# ATSAM4LC8C register map
Vendor: Atmel Corporation; Series: SAM4L; File version: A
CPU: CM4 r0p1, little endian, MPU, no FPU, 4 interrupt priority bits
Registers are 32-bit, write-only, reset 0x0 unless marked. A register's access mark holds for its fields unless they carry their own. Offsets are from the block's base; [hi:lo] are bit positions; {n}, {i} and the like mark numbered series.

## PM — Power Manager
Base 0x400E0000; register names take the prefix PM_
0x00 MCCTRL rw — Main Clock Control
  [2:0] MCSEL — Main Clock Select
    0=RCSYS (System RC oscillator); 1=OSC0 (Oscillator0); 2=PLL; 3=DFLL; 4=RC80M (80 MHz RC oscillator); 5=RCFAST (4/8/12 MHz RC oscillator); 6=RC1M (1 MHz RC oscillator)
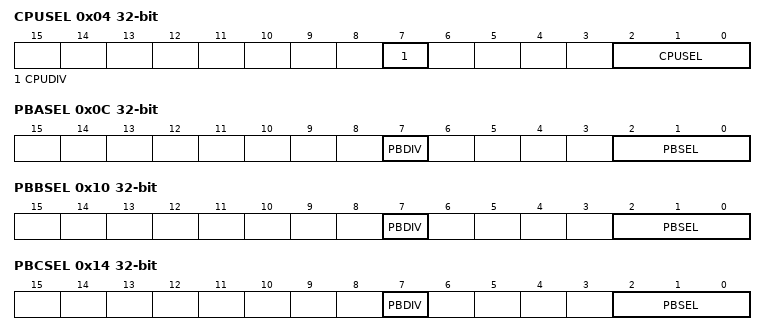
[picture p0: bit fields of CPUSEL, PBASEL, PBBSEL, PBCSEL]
0x04 CPUSEL rw — CPU Clock Select
  [7] CPUDIV — CPU Division
  [2:0] CPUSEL — CPU Clock Select
    0=fCPU:fmain. CPUDIV:; 1=fCPU:fmain / 2^(CPUSEL+1)
0x0C PBASEL rw — PBA Clock Select
  [7] PBDIV — PBA Division Select
  [2:0] PBSEL — PBA Clock Select
0x10 PBBSEL rw — PBB Clock Select
  [7] PBDIV — PBB Division Select
  [2:0] PBSEL — PBB Clock Select
0x14 PBCSEL rw — PBC Clock Select
  [7] PBDIV — PBC Division Select
  [2:0] PBSEL — PBC Clock Select
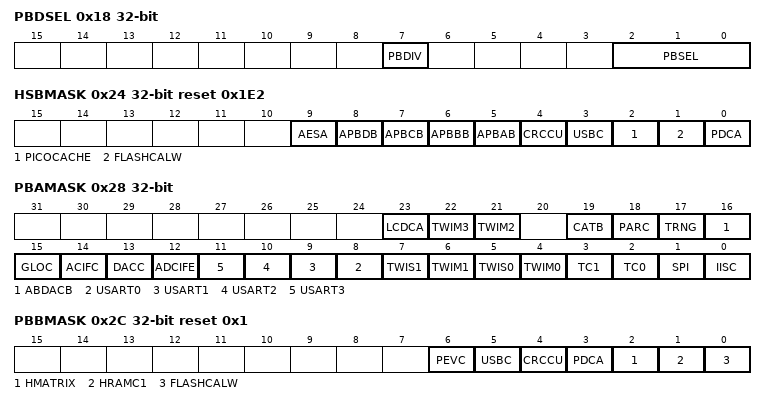
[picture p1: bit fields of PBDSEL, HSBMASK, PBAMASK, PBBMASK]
0x18 PBDSEL rw — PBD Clock Select
  [7] PBDIV — PBD Division Select
  [2:0] PBSEL — PBD Clock Select
0x20 CPUMASK rw reset 0x1
  [0] OCD — OCD CPU Clock Mask
0x24 HSBMASK rw reset 0x1E2
  [9] AESA — AESA HSB Clock Mask
  [8] APBDB — APBD Bridge HSB Clock Mask
  [7] APBCB — APBC Bridge HSB Clock Mask
  [6] APBBB — APBB Bridge HSB Clock Mask
  [5] APBAB — APBA Bridge HSB Clock Mask
  [4] CRCCU — CRCCU HSB Clock Mask
  [3] USBC — USBC HSB Clock Mask
  [2] PICOCACHE — FLASHCALW picoCache RAM HSB Clock Mask
  [1] FLASHCALW — FLASHCALW HSB Clock Mask
  [0] PDCA — PDCA HSB Clock Mask
0x28 PBAMASK rw
  [23] LCDCA — LCDCA APB Clock Enable
  [22] TWIM3 — TWIM3 APB Clock Enable
  [21] TWIM2 — TWIM2 APB Clock Enable
  [19] CATB — CATB APB Clock Enable
  [18] PARC — PARC APB Clock Enable
  [17] TRNG — TRNG APB Clock Enable
  [16] ABDACB — ABDACB APB Clock Enable
  [15] GLOC — GLOC APB Clock Enable
  [14] ACIFC — ACIFC APB Clock Enable
  [13] DACC — DACC APB Clock Enable
  [12] ADCIFE — ADCIFE APB Clock Enable
  [n+8] USART{n} (n=0..3) — USART{n} APB Clock Enable
  [7] TWIS1 — TWIS1 APB Clock Enable
  [6] TWIM1 — TWIM1 APB Clock Enable
  [5] TWIS0 — TWIS0 APB Clock Enable
  [4] TWIM0 — TWIM0 APB Clock Enable
  [3] TC1 — TC1 APB Clock Enable
  [2] TC0 — TC0 APB Clock Enable
  [1] SPI — SPI APB Clock Enable
  [0] IISC — IISC APB Clock Enable
0x2C PBBMASK rw reset 0x1
  [6] PEVC — PEVC APB Clock Enable
  [5] USBC — USBC APB Clock Enable
  [4] CRCCU — CRCCU APB Clock Enable
  [3] PDCA — PDCA APB Clock Enable
  [2] HMATRIX — HMATRIX APB Clock Enable
  [1] HRAMC1 — HRAMC1 APB Clock Enable
  [0] FLASHCALW — FLASHCALW APB Clock Enable
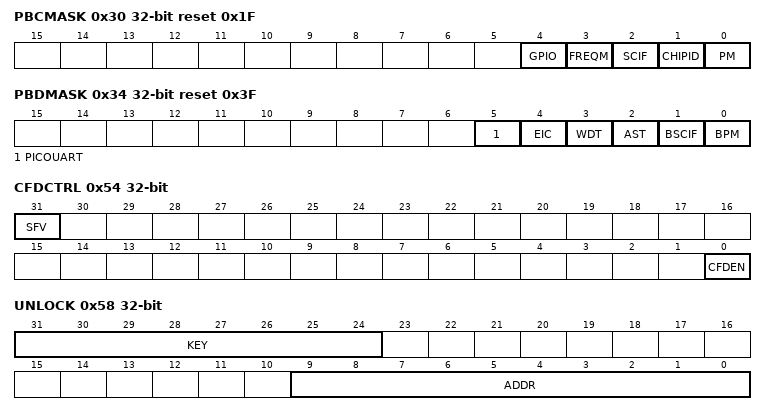
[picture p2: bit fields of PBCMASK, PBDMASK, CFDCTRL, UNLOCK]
0x30 PBCMASK rw reset 0x1F
  [4] GPIO — GPIO APB Clock Enable
  [3] FREQM — FREQM APB Clock Enable
  [2] SCIF — SCIF APB Clock Enable
  [1] CHIPID — CHIPID APB Clock Enable
  [0] PM — PM APB Clock Enable
0x34 PBDMASK rw reset 0x3F
  [5] PICOUART — PICOUART APB Clock Enable
  [4] EIC — EIC APB Clock Enable
  [3] WDT — WDT APB Clock Enable
  [2] AST — AST APB Clock Enable
  [1] BSCIF — BSCIF APB Clock Enable
  [0] BPM — BPM APB Clock Enable
0x40 PBADIVMASK rw — PBA Divided Clock Mask
0x54 CFDCTRL rw — Clock Failure Detector Control
  [31] SFV — Store Final Value
  [0] CFDEN — Clock Failure Detection Enable
0x58 UNLOCK
  [31:24] KEY — Unlock Key
  [9:0] ADDR — Unlock Address
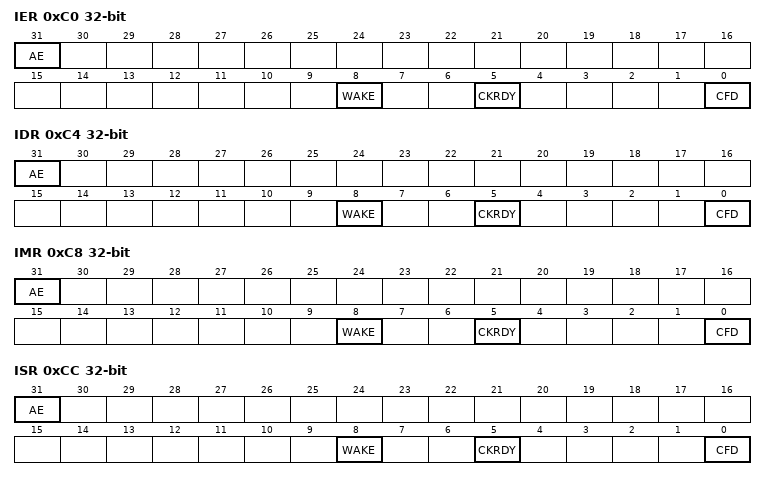
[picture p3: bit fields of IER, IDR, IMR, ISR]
0xC0 IER — Interrupt Enable Register
  [31] AE — Access Error Interrupt Enable
  [8] WAKE — Wake up Interrupt Enable
    0=No effect; 1=Disable Interrupt
  [5] CKRDY — Clock Ready Interrupt Enable
  [0] CFD — Clock Failure Detected Interrupt Enable
0xC4 IDR — Interrupt Disable Register
  [31] AE — Access Error Interrupt Disable
  [8] WAKE — Wake up Interrupt Disable
    0=No effect; 1=Disable Interrupt
  [5] CKRDY — Clock Ready Interrupt Disable
  [0] CFD — Clock Failure Detected Interrupt Disable
0xC8 IMR ro — Interrupt Mask Register
  [31] AE — Access Error Interrupt Mask
  [8] WAKE — Wake up Interrupt Mask
    0=No effect; 1=Disable Interrupt
  [5] CKRDY — Clock Ready Interrupt Mask
  [0] CFD — Clock Failure Detected Interrupt Mask
0xCC ISR ro — Interrupt Status Register
  [31] AE — Access Error Interrupt Status
  [8] WAKE — Wake up Interrupt Status
    0=No effect; 1=Disable Interrupt
  [5] CKRDY — Clock Ready Interrupt Status
  [0] CFD — Clock Failure Detected Interrupt Status
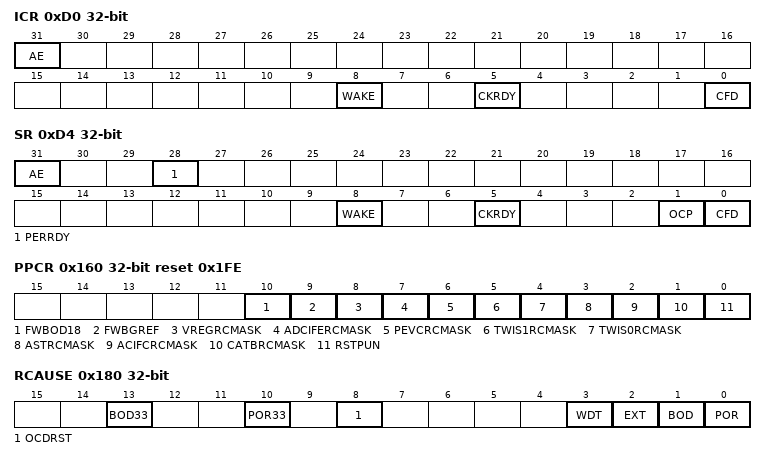
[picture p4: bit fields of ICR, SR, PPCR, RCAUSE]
0xD0 ICR — Interrupt Clear Register
  [31] AE — Access Error Interrupt Status Clear
  [8] WAKE — Wake up Interrupt Status Clear
  [5] CKRDY — Clock Ready Interrupt Status Clear
  [0] CFD — Clock Failure Detected Interrupt Status Clear
0xD4 SR ro — Status Register
  [31] AE — Access Error
  [28] PERRDY — Peripheral Ready
  [8] WAKE — Wake up
    0=No effect; 1=Disable Interrupt
  [5] CKRDY — Clock Ready
  [1] OCP — Over Clock Detected
  [0] CFD — Clock Failure Detected
0x160 PPCR rw reset 0x1FE — Peripheral Power Control Register
  [10] FWBOD18 — Flash Wait BOD18
  [9] FWBGREF — Flash Wait BGREF
  [8] VREGRCMASK — VREG Request Clock Mask
  [7] ADCIFERCMASK — ADCIFE Request Clock Mask
  [6] PEVCRCMASK — PEVC Request Clock Mask
  [5] TWIS1RCMASK — TWIS1 Request Clock Mask
  [4] TWIS0RCMASK — TWIS0 Request Clock Mask
  [3] ASTRCMASK — AST Request Clock Mask
  [2] ACIFCRCMASK — ACIFC Request Clock Mask
  [1] CATBRCMASK — CAT Request Clock Mask
  [0] RSTPUN — Reset Pullup
0x180 RCAUSE ro — Reset Cause Register
  [13] BOD33 — Brown-out 3.3V Reset
  [10] POR33 — Power-on Reset
  [8] OCDRST — OCD Reset
  [3] WDT — Watchdog Reset
  [2] EXT — External Reset Pin
  [1] BOD — Brown-out Reset
  [0] POR — Power-on Reset
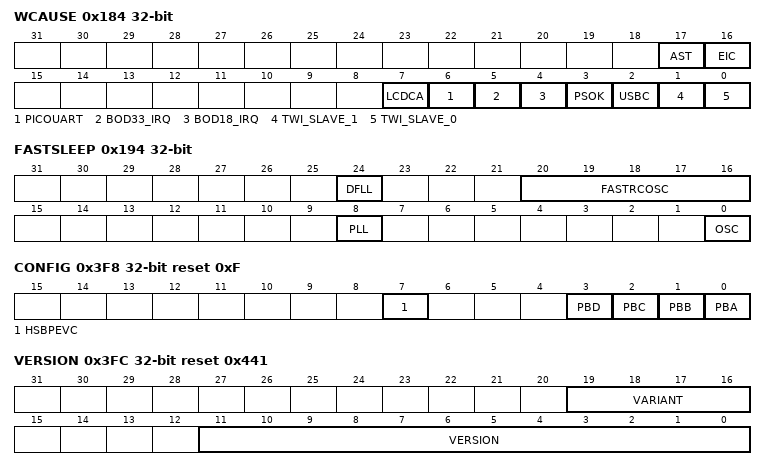
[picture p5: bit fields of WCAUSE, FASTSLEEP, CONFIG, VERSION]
0x184 WCAUSE ro — Wake Cause Register
  [17] AST — Asynchronous Timer
  [16] EIC — External Interrupt Controller
  [7] LCDCA — LCD Controller
  [6] PICOUART — Picopower UART
  [5] BOD33_IRQ — BOD33 Interrupt
  [4] BOD18_IRQ — BOD18 Interrupt
  [3] PSOK — Power Scaling OK
  [2] USBC — USB Device and Embedded Host Interface
  [1] TWI_SLAVE_1 — Two-wire Slave Interface 1
  [0] TWI_SLAVE_0 — Two-wire Slave Interface 0
0x188 AWEN rw — Asynchronous Wake Enable
  [31:0] AWEN — Asynchronous Wake Up
0x190 OBS rw — Obsvervability
0x194 FASTSLEEP rw
  [24] DFLL
  [20:16] FASTRCOSC — RC80 or FLO
  [8] PLL
  [0] OSC — Oscillator
0x3F8 CONFIG ro reset 0xF — Configuration Register
  [7] HSBPEVC — HSB PEVC Clock Implemented
  [3] PBD — APBD Implemented
  [2] PBC — APBC Implemented
  [1] PBB — APBB Implemented
  [0] PBA — APBA Implemented
0x3FC VERSION ro reset 0x441
  [19:16] VARIANT — Variant number
  [11:0] VERSION — Version number

## Notices in the file
Atmel Microcontroller Software Support
Copyright (c) 2016 Atmel Corporation,
a wholly owned subsidiary of Microchip Technology Inc.
Licensed under the Apache License, Version 2.0 (the "License");
you may not use this file except in compliance with the License.
You may obtain a copy of the Licence at
http://www.apache.org/licenses/LICENSE-2.0
Unless required by applicable law or agreed to in writing, software
distributed under the License is distributed on an "AS IS" BASIS,
WITHOUT WARRANTIES OR CONDITIONS OF ANY KIND, either express or implied.
See the License for the specific language governing permissions and
limitations under the License.
